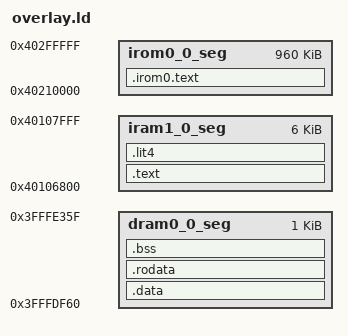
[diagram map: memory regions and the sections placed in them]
/* This linker script generated from xt-genldscripts.tpp for LSP . */
/* Linker Script for ld -N */
MEMORY
{
  dram0_0_seg :		org = 0x3FFFDF60, len = 0x00400    
  iram1_0_seg :		org = 0x40106800, len = 0x01800
  irom0_0_seg :		org = 0x40210000, len = 0xF0000
}

PHDRS
{
  dram0_0_phdr PT_LOAD;
  dram0_0_bss_phdr PT_LOAD;
  iram1_0_phdr PT_LOAD;
  irom0_0_phdr PT_LOAD;
}


/*  Default entry point:  */
PROVIDE(_memmap_vecbase_reset = 0x40000000);
/* Various memory-map dependent cache attribute settings: */
_memmap_cacheattr_wb_base = 0x00000110;
_memmap_cacheattr_wt_base = 0x00000110;
_memmap_cacheattr_bp_base = 0x00000220;
_memmap_cacheattr_unused_mask = 0xFFFFF00F;
_memmap_cacheattr_wb_trapnull = 0x2222211F;
_memmap_cacheattr_wba_trapnull = 0x2222211F;
_memmap_cacheattr_wbna_trapnull = 0x2222211F;
_memmap_cacheattr_wt_trapnull = 0x2222211F;
_memmap_cacheattr_bp_trapnull = 0x2222222F;
_memmap_cacheattr_wb_strict = 0xFFFFF11F;
_memmap_cacheattr_wt_strict = 0xFFFFF11F;
_memmap_cacheattr_bp_strict = 0xFFFFF22F;
_memmap_cacheattr_wb_allvalid = 0x22222112;
_memmap_cacheattr_wt_allvalid = 0x22222112;
_memmap_cacheattr_bp_allvalid = 0x22222222;
PROVIDE(_memmap_cacheattr_reset = _memmap_cacheattr_wb_trapnull);

SECTIONS
{

  .data : ALIGN(4)
  {
    _data_start = ABSOLUTE(.);
    *(.data)
    *(.data.*)
    *(.gnu.linkonce.d.*)
    *(.data1)
    *(.sdata)
    *(.sdata.*)
    *(.gnu.linkonce.s.*)
    *(.sdata2)
    *(.sdata2.*)
    *(.gnu.linkonce.s2.*)
    *(.jcr)
    _data_end = ABSOLUTE(.);
  } >dram0_0_seg :dram0_0_phdr

  .rodata : ALIGN(4)
  {
    _rodata_start = ABSOLUTE(.);
    *(.rodata)
    *(.rodata.*)
    *(.gnu.linkonce.r.*)
    *(.rodata1)
    *(.dynamic)
    *(.gnu.version_d)
    . = ALIGN(4);		/* this table MUST be 4-byte aligned */
    _bss_table_start = ABSOLUTE(.);
/*    LONG(_bss_start)
    LONG(_bss_end) */
    _bss_table_end = ABSOLUTE(.);
    _rodata_end = ABSOLUTE(.);
  } >dram0_0_seg :dram0_0_phdr

  .bss ALIGN(8) (NOLOAD) : ALIGN(4)
  {
    . = ALIGN (8);
    _bss_start = ABSOLUTE(.);
    *(.dynsbss)
    *(.sbss)
    *(.sbss.*)
    *(.gnu.linkonce.sb.*)
    *(.scommon)
    *(.sbss2)
    *(.sbss2.*)
    *(.gnu.linkonce.sb2.*)
    *(.dynbss)
    *(.bss)
    *(.bss.*)
    *(.gnu.linkonce.b.*)
    *(COMMON)
    . = ALIGN (8);
    _bss_end = ABSOLUTE(.);
    _heap_start = ABSOLUTE(.);
  } >dram0_0_seg :dram0_0_bss_phdr

  .text : ALIGN(4)
  {
    _stext = .;
    _text_start = ABSOLUTE(.);
    *(.entry.text)
    *(.init.literal)
    *(.init)
    *(.literal .text .literal.* .text.* .stub .gnu.warning .gnu.linkonce.literal.* .gnu.linkonce.t.*.literal .gnu.linkonce.t.*)
    *(.fini.literal)
    *(.fini)
    *(.gnu.version)
    . = ALIGN (4);
    _text_end = ABSOLUTE(.);
    _etext = .;
  } >iram1_0_seg :iram1_0_phdr

  .lit4 : ALIGN(4)
  {
    _lit4_start = ABSOLUTE(.);
    *(.iram.data)
    *(*.lit4)
    *(.lit4.*)
    *(.gnu.linkonce.lit4.*)
    _lit4_end = ABSOLUTE(.);
  } >iram1_0_seg :iram1_0_phdr

  .irom0.text : ALIGN(4)
  {
    _irom0_text_start = ABSOLUTE(.);
    *(.irom0.literal .irom.literal .irom.text.literal .irom0.text .irom.text)
    _irom0_text_end = ABSOLUTE(.);
  } >irom0_0_seg :irom0_0_phdr

}

/* get ROM code address */
INCLUDE "../ld/eagle.rom.addr.v6.ld"
INCLUDE "../ld/labels.ld"

